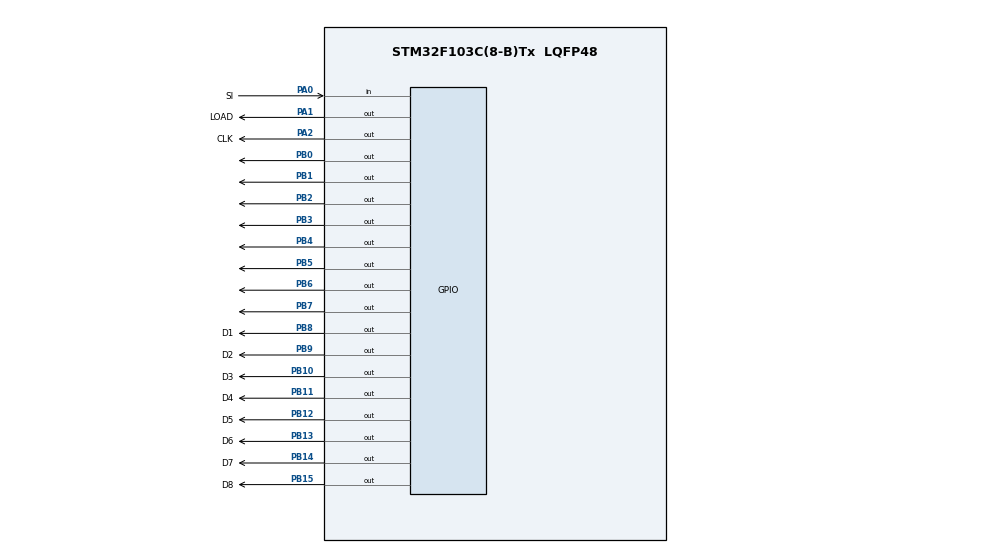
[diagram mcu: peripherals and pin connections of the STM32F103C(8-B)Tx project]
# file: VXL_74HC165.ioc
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Mcu.Family=STM32F1
Mcu.Name=STM32F103C(8-B)Tx
Mcu.Package=LQFP48
NVIC.PriorityGroup=NVIC_PRIORITYGROUP_4
PA0-WKUP.GPIO_Label=SI
PA0-WKUP.Signal=GPIO_Input
PA1.GPIO_Label=LOAD
PA1.Signal=GPIO_Output
PA13.Mode=Serial_Wire
PA13.Signal=SYS_JTMS-SWDIO
PA14.Mode=Serial_Wire
PA14.Signal=SYS_JTCK-SWCLK
PA2.GPIO_Label=CLK
PA2.Signal=GPIO_Output
PB0.Signal=GPIO_Output
PB1.Signal=GPIO_Output
PB10.GPIO_Label=D3
PB10.Signal=GPIO_Output
PB11.GPIO_Label=D4
PB11.Signal=GPIO_Output
PB12.GPIO_Label=D5
PB12.Signal=GPIO_Output
PB13.GPIO_Label=D6
PB13.Signal=GPIO_Output
PB14.GPIO_Label=D7
PB14.Signal=GPIO_Output
PB15.GPIO_Label=D8
PB15.Signal=GPIO_Output
PB2.Signal=GPIO_Output
PB3.Signal=GPIO_Output
PB4.Signal=GPIO_Output
PB5.Signal=GPIO_Output
PB6.Signal=GPIO_Output
PB7.Signal=GPIO_Output
PB8.GPIO_Label=D1
PB8.Signal=GPIO_Output
PB9.GPIO_Label=D2
PB9.Signal=GPIO_Output
ProjectManager.HeapSize=0x200
ProjectManager.StackSize=0x400
ProjectManager.TargetToolchain=MDK-ARM V5.32
RCC.APB1Freq_Value=8000000
RCC.APB2Freq_Value=8000000
board=custom

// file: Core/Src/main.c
/* USER CODE BEGIN Header */
/**
  ******************************************************************************
  * @file           : main.c
  * @brief          : Main program body
  ******************************************************************************
  * @attention
  *
  * Copyright (c) 2023 STMicroelectronics.
  * All rights reserved.
  *
  * This software is licensed under terms that can be found in the LICENSE file
  * in the root directory of this software component.
  * If no LICENSE file comes with this software, it is provided AS-IS.
  *
  ******************************************************************************
  */
/* USER CODE END Header */
#include "main.h"

void SystemClock_Config(void);
static void MX_GPIO_Init(void);

int main(void)
{

  /* MCU Configuration--------------------------------------------------------*/

  /* Reset of all peripherals, Initializes the Flash interface and the Systick. */
  HAL_Init();

  /* Configure the system clock */
  SystemClock_Config();

  /* Initialize all configured peripherals */
  MX_GPIO_Init();
  /* USER CODE BEGIN 2 */
	HAL_GPIO_WritePin(LOAD_GPIO_Port, LOAD_Pin,GPIO_PIN_SET);
	HAL_GPIO_WritePin(CLK_GPIO_Port, CLK_Pin,GPIO_PIN_SET);
	uint8_t DATAIN = 0;
  /* USER CODE END 2 */

  /* Infinite loop */
  while (1)
  {
		HAL_GPIO_WritePin(LOAD_GPIO_Port, LOAD_Pin,GPIO_PIN_RESET);
		HAL_GPIO_WritePin(LOAD_GPIO_Port, LOAD_Pin,GPIO_PIN_SET);
		DATAIN =0;
		for (uint8_t i=0;i<8;i++) {
			HAL_GPIO_WritePin(CLK_GPIO_Port, CLK_Pin,GPIO_PIN_RESET);
			DATAIN = DATAIN|HAL_GPIO_ReadPin(SI_GPIO_Port,SI_Pin);
			HAL_GPIO_WritePin(CLK_GPIO_Port, CLK_Pin,GPIO_PIN_SET);
			if (i<7) DATAIN = DATAIN << 1;
		}
		GPIOB->ODR = DATAIN<<8;// 0x--00
  }
}

void SystemClock_Config(void)
{
  RCC_OscInitTypeDef RCC_OscInitStruct = {0};
  RCC_ClkInitTypeDef RCC_ClkInitStruct = {0};

  /** Initializes the RCC Oscillators according to the specified parameters
  * in the RCC_OscInitTypeDef structure.
  */
  RCC_OscInitStruct.OscillatorType = RCC_OSCILLATORTYPE_HSI;
  RCC_OscInitStruct.HSIState = RCC_HSI_ON;
  RCC_OscInitStruct.HSICalibrationValue = RCC_HSICALIBRATION_DEFAULT;
  RCC_OscInitStruct.PLL.PLLState = RCC_PLL_NONE;
  if (HAL_RCC_OscConfig(&RCC_OscInitStruct) != HAL_OK)
  {
    Error_Handler();
  }

  /** Initializes the CPU, AHB and APB buses clocks
  */
  RCC_ClkInitStruct.ClockType = RCC_CLOCKTYPE_HCLK|RCC_CLOCKTYPE_SYSCLK
                              |RCC_CLOCKTYPE_PCLK1|RCC_CLOCKTYPE_PCLK2;
  RCC_ClkInitStruct.SYSCLKSource = RCC_SYSCLKSOURCE_HSI;
  RCC_ClkInitStruct.AHBCLKDivider = RCC_SYSCLK_DIV1;
  RCC_ClkInitStruct.APB1CLKDivider = RCC_HCLK_DIV1;
  RCC_ClkInitStruct.APB2CLKDivider = RCC_HCLK_DIV1;

  if (HAL_RCC_ClockConfig(&RCC_ClkInitStruct, FLASH_LATENCY_0) != HAL_OK)
  {
    Error_Handler();
  }
}

static void MX_GPIO_Init(void)
{
  GPIO_InitTypeDef GPIO_InitStruct = {0};

  /* GPIO Ports Clock Enable */
  __HAL_RCC_GPIOC_CLK_ENABLE();
  __HAL_RCC_GPIOD_CLK_ENABLE();
  __HAL_RCC_GPIOA_CLK_ENABLE();
  __HAL_RCC_GPIOB_CLK_ENABLE();

  /*Configure GPIO pin Output Level */
  HAL_GPIO_WritePin(GPIOA, LOAD_Pin|CLK_Pin, GPIO_PIN_RESET);

  /*Configure GPIO pin Output Level */
  HAL_GPIO_WritePin(GPIOB, GPIO_PIN_0|GPIO_PIN_1|GPIO_PIN_2|D3_Pin
                          |D4_Pin|D5_Pin|D6_Pin|D7_Pin
                          |D8_Pin|GPIO_PIN_3|GPIO_PIN_4|GPIO_PIN_5
                          |GPIO_PIN_6|GPIO_PIN_7|D1_Pin|D2_Pin, GPIO_PIN_RESET);

  /*Configure GPIO pins : PC13 PC14 PC15 */
  GPIO_InitStruct.Pin = GPIO_PIN_13|GPIO_PIN_14|GPIO_PIN_15;
  GPIO_InitStruct.Mode = GPIO_MODE_ANALOG;
  HAL_GPIO_Init(GPIOC, &GPIO_InitStruct);

  /*Configure GPIO pins : PD0 PD1 */
  GPIO_InitStruct.Pin = GPIO_PIN_0|GPIO_PIN_1;
  GPIO_InitStruct.Mode = GPIO_MODE_ANALOG;
  HAL_GPIO_Init(GPIOD, &GPIO_InitStruct);

  /*Configure GPIO pin : SI_Pin */
  GPIO_InitStruct.Pin = SI_Pin;
  GPIO_InitStruct.Mode = GPIO_MODE_INPUT;
  GPIO_InitStruct.Pull = GPIO_NOPULL;
  HAL_GPIO_Init(SI_GPIO_Port, &GPIO_InitStruct);

  /*Configure GPIO pins : LOAD_Pin CLK_Pin */
  GPIO_InitStruct.Pin = LOAD_Pin|CLK_Pin;
  GPIO_InitStruct.Mode = GPIO_MODE_OUTPUT_PP;
  GPIO_InitStruct.Pull = GPIO_NOPULL;
  GPIO_InitStruct.Speed = GPIO_SPEED_FREQ_LOW;
  HAL_GPIO_Init(GPIOA, &GPIO_InitStruct);

  /*Configure GPIO pins : PA3 PA4 PA5 PA6
                           PA7 PA8 PA9 PA10
                           PA11 PA12 PA15 */
  GPIO_InitStruct.Pin = GPIO_PIN_3|GPIO_PIN_4|GPIO_PIN_5|GPIO_PIN_6
                          |GPIO_PIN_7|GPIO_PIN_8|GPIO_PIN_9|GPIO_PIN_10
                          |GPIO_PIN_11|GPIO_PIN_12|GPIO_PIN_15;
  GPIO_InitStruct.Mode = GPIO_MODE_ANALOG;
  HAL_GPIO_Init(GPIOA, &GPIO_InitStruct);

  /*Configure GPIO pins : PB0 PB1 PB2 D3_Pin
                           D4_Pin D5_Pin D6_Pin D7_Pin
                           D8_Pin PB3 PB4 PB5
                           PB6 PB7 D1_Pin D2_Pin */
  GPIO_InitStruct.Pin = GPIO_PIN_0|GPIO_PIN_1|GPIO_PIN_2|D3_Pin
                          |D4_Pin|D5_Pin|D6_Pin|D7_Pin
                          |D8_Pin|GPIO_PIN_3|GPIO_PIN_4|GPIO_PIN_5
                          |GPIO_PIN_6|GPIO_PIN_7|D1_Pin|D2_Pin;
  GPIO_InitStruct.Mode = GPIO_MODE_OUTPUT_PP;
  GPIO_InitStruct.Pull = GPIO_NOPULL;
  GPIO_InitStruct.Speed = GPIO_SPEED_FREQ_LOW;
  HAL_GPIO_Init(GPIOB, &GPIO_InitStruct);

  /*Configure peripheral I/O remapping */
  __HAL_AFIO_REMAP_PD01_ENABLE();

}

void Error_Handler(void)
{
  __disable_irq();
  while (1)
  {
  }
}
